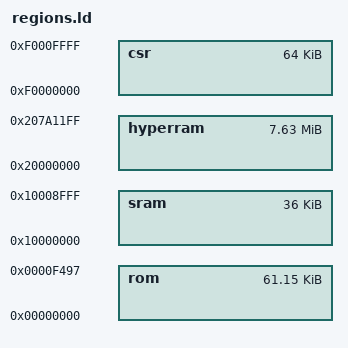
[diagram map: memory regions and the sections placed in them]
MEMORY {
	rom : ORIGIN = 0x00000000, LENGTH = 0x0000f498
	sram : ORIGIN = 0x10000000, LENGTH = 0x00009000
	hyperram : ORIGIN = 0x20000000, LENGTH = 0x007a1200
	csr : ORIGIN = 0xf0000000, LENGTH = 0x00010000
}
